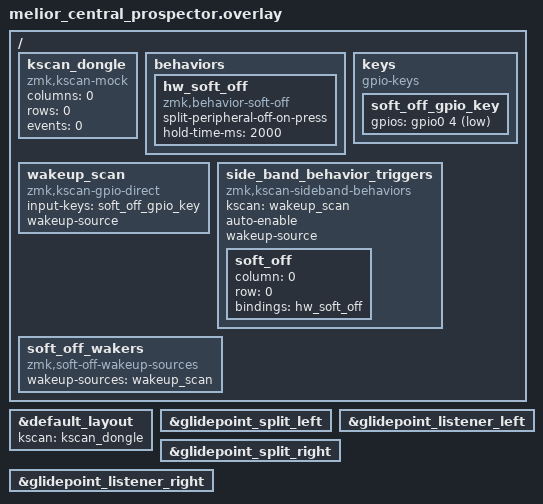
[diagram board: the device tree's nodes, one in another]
#include "melior.dtsi"

/ {
    kscan_dongle: kscan_dongle {
        compatible = "zmk,kscan-mock";
        columns = <0>;
        rows = <0>;
        events = <0>;
    };
};

/ {
    behaviors {
        hw_soft_off: hw_soft_off {
            compatible = "zmk,behavior-soft-off";
            #binding-cells = <0>;
            split-peripheral-off-on-press; // Turn peripheral off immediately for reliability
            hold-time-ms = <2000>; // Only turn off if the key is held for 2 seconds or longer.
        };
    };
};

/ {
    keys {
        compatible = "gpio-keys";
        soft_off_gpio_key: soft_off_gpio_key {
            gpios = <&gpio0 4 (GPIO_ACTIVE_LOW | GPIO_PULL_UP)>;
        };
    };
};

/ {
    wakeup_scan: wakeup_scan {
        compatible = "zmk,kscan-gpio-direct";
        input-keys = <&soft_off_gpio_key>;
        wakeup-source;
    };
};

/ {
    side_band_behavior_triggers: side_band_behavior_triggers {
        compatible = "zmk,kscan-sideband-behaviors";

        kscan = <&wakeup_scan>;
        auto-enable;
        wakeup-source;

        soft_off {
            column = <0>;
            row = <0>;
            bindings = <&hw_soft_off>;
        };
    };
};

/ {
    soft_off_wakers {
        compatible = "zmk,soft-off-wakeup-sources";
        wakeup-sources = <&wakeup_scan>;
    };
};

&default_layout  {
    kscan = <&kscan_dongle>;
};

// == Input devices ==
// Input devices on peripheral parts
// Enabling input listeners and input-split to receive input events from peripherals
&glidepoint_split_left { status = "okay"; };
&glidepoint_listener_left { status = "okay"; };
&glidepoint_split_right { status = "okay"; };
&glidepoint_listener_right { status = "okay"; };

